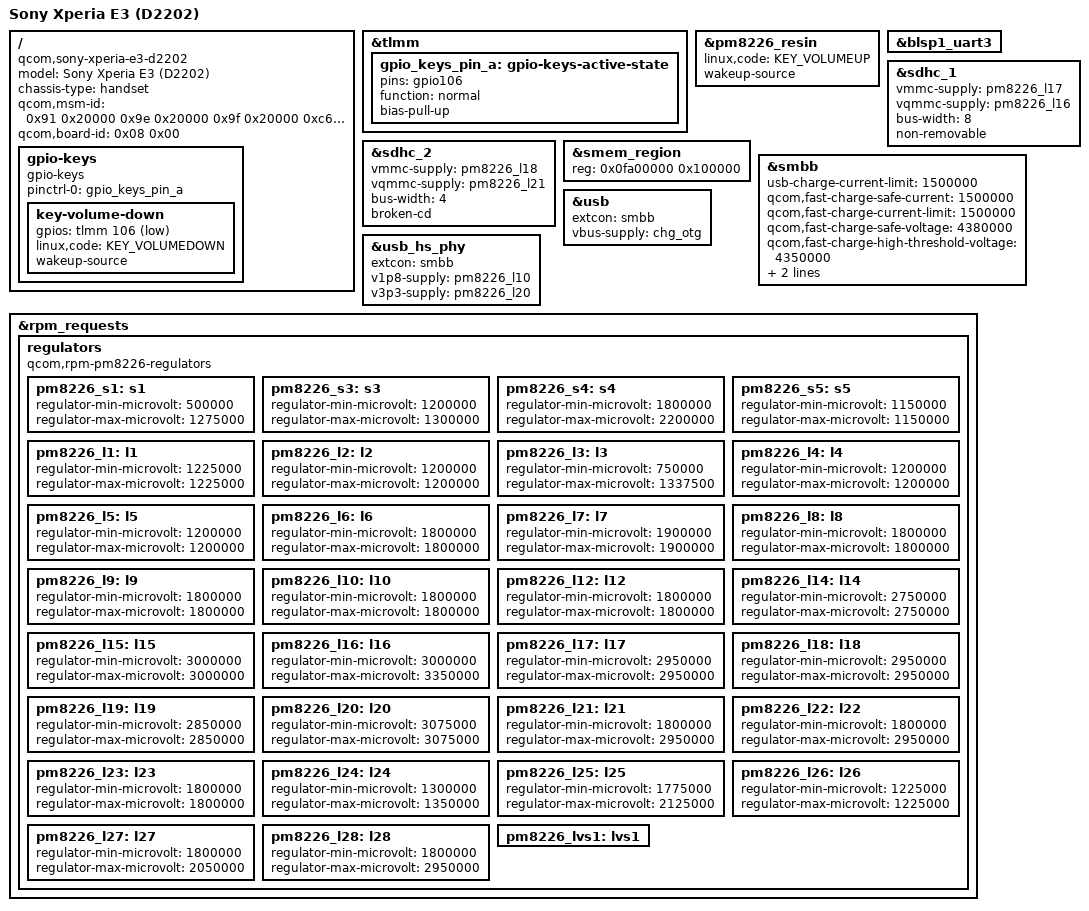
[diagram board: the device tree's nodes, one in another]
// SPDX-License-Identifier: GPL-2.0-only

#include <dt-bindings/gpio/gpio.h>

#include "qcom-msm8226.dtsi"
#include "qcom-pm8226.dtsi"

/ {
	model = "Sony Xperia E3 (D2202)";
	compatible = "qcom,sony-xperia-e3-d2202", "qcom,sony-xperia-e3", "qcom,msm8226";
	chassis-type = "handset";
	qcom,msm-id = <0x91 0x20000
		       0x9e 0x20000
		       0x9f 0x20000
		       0xc6 0x20000
		       0xcd 0x20000
		       0xdc 0x20000
		       0xdd 0x20000
		       0xde 0x20000
		       0xdf 0x20000>;
	qcom,board-id = <0x08 0x00>;

	gpio-keys {
		compatible = "gpio-keys";

		pinctrl-names = "default";
		pinctrl-0 = <&gpio_keys_pin_a>;

		key-volume-down {
			gpios = <&tlmm 106 GPIO_ACTIVE_LOW>;
			linux,code = <KEY_VOLUMEDOWN>;
			wakeup-source;
		};
	};
};

&tlmm {
	gpio_keys_pin_a: gpio-keys-active-state {
		pins = "gpio106";
		function = "normal";

		bias-pull-up;
	};
};

&pm8226_resin {
	status = "okay";

	linux,code = <KEY_VOLUMEUP>;
	wakeup-source;
};

&blsp1_uart3 {
	status = "okay";
};

&sdhc_1 {
	vmmc-supply = <&pm8226_l17>;
	vqmmc-supply = <&pm8226_l16>;

	bus-width = <8>;
	non-removable;

	status = "okay";
};

&sdhc_2 {
	vmmc-supply = <&pm8226_l18>;
	vqmmc-supply = <&pm8226_l21>;

	bus-width = <4>;
	broken-cd;

	status = "okay";
};

&smem_region {
  reg = <0x0fa00000 0x100000>;
};

&smbb {
	usb-charge-current-limit = <1500000>;
	qcom,fast-charge-safe-current = <1500000>;
	qcom,fast-charge-current-limit = <1500000>;
	qcom,fast-charge-safe-voltage = <4380000>;
	qcom,fast-charge-high-threshold-voltage = <4350000>;
	qcom,auto-recharge-threshold-voltage = <4240000>;
	qcom,minimum-input-voltage = <4300000>;
};

&usb {
	status = "okay";

	extcon = <&smbb>;
	vbus-supply = <&chg_otg>;
};

&usb_hs_phy {
	extcon = <&smbb>;
	v1p8-supply = <&pm8226_l10>;
	v3p3-supply = <&pm8226_l20>;
};

&rpm_requests {
	regulators {
		compatible = "qcom,rpm-pm8226-regulators";
		
		pm8226_s1: s1 {
			regulator-min-microvolt = <500000>;
			regulator-max-microvolt = <1275000>;
		};

		pm8226_s3: s3 {
			regulator-min-microvolt = <1200000>;
			regulator-max-microvolt = <1300000>;
		};
		pm8226_s4: s4 {
			regulator-min-microvolt = <1800000>;
			regulator-max-microvolt = <2200000>;
		};
		pm8226_s5: s5 {
			regulator-min-microvolt = <1150000>;
			regulator-max-microvolt = <1150000>;
		};

		pm8226_l1: l1 {
			regulator-min-microvolt = <1225000>;
			regulator-max-microvolt = <1225000>;
		};
		pm8226_l2: l2 {
			regulator-min-microvolt = <1200000>;
			regulator-max-microvolt = <1200000>;
		};
		pm8226_l3: l3 {
			regulator-min-microvolt = <750000>;
			regulator-max-microvolt = <1337500>;
		};
		pm8226_l4: l4 {
			regulator-min-microvolt = <1200000>;
			regulator-max-microvolt = <1200000>;
		};
		pm8226_l5: l5 {
			regulator-min-microvolt = <1200000>;
			regulator-max-microvolt = <1200000>;
		};
		pm8226_l6: l6 {
			regulator-min-microvolt = <1800000>;
			regulator-max-microvolt = <1800000>;
		};
		pm8226_l7: l7 {
			regulator-min-microvolt = <1900000>;
			regulator-max-microvolt = <1900000>;
		};
		pm8226_l8: l8 {
			regulator-min-microvolt = <1800000>;
			regulator-max-microvolt = <1800000>;
		};
		pm8226_l9: l9 {
			regulator-min-microvolt = <1800000>;
			regulator-max-microvolt = <1800000>;
		};
		pm8226_l10: l10 {
			regulator-min-microvolt = <1800000>;
			regulator-max-microvolt = <1800000>;
		};
		pm8226_l12: l12 {
			regulator-min-microvolt = <1800000>;
			regulator-max-microvolt = <1800000>;
		};
		pm8226_l14: l14 {
			regulator-min-microvolt = <2750000>;
			regulator-max-microvolt = <2750000>;
		};
		pm8226_l15: l15 {
			regulator-min-microvolt = <3000000>;
			regulator-max-microvolt = <3000000>;
		};
		pm8226_l16: l16 {
			regulator-min-microvolt = <3000000>;
			regulator-max-microvolt = <3350000>;
		};
		pm8226_l17: l17 {
			regulator-min-microvolt = <2950000>;
			regulator-max-microvolt = <2950000>;
		};
		pm8226_l18: l18 {
			regulator-min-microvolt = <2950000>;
			regulator-max-microvolt = <2950000>;
		};
		pm8226_l19: l19 {
			regulator-min-microvolt = <2850000>;
			regulator-max-microvolt = <2850000>;
		};
		pm8226_l20: l20 {
			regulator-min-microvolt = <3075000>;
			regulator-max-microvolt = <3075000>;
		};
		pm8226_l21: l21 {
			regulator-min-microvolt = <1800000>;
			regulator-max-microvolt = <2950000>;
		};
		pm8226_l22: l22 {
			regulator-min-microvolt = <1800000>;
			regulator-max-microvolt = <2950000>;
		};
		pm8226_l23: l23 {
			regulator-min-microvolt = <1800000>;
			regulator-max-microvolt = <1800000>;
		};
		pm8226_l24: l24 {
			regulator-min-microvolt = <1300000>;
			regulator-max-microvolt = <1350000>;
		};
		pm8226_l25: l25 {
			regulator-min-microvolt = <1775000>;
			regulator-max-microvolt = <2125000>;
		};
		pm8226_l26: l26 {
			regulator-min-microvolt = <1225000>;
			regulator-max-microvolt = <1225000>;
		};
		pm8226_l27: l27 {
			regulator-min-microvolt = <1800000>;
			regulator-max-microvolt = <2050000>;
		};
		pm8226_l28: l28 {
			regulator-min-microvolt = <1800000>;
			regulator-max-microvolt = <2950000>;
		};

		pm8226_lvs1: lvs1 {};
	};
};
